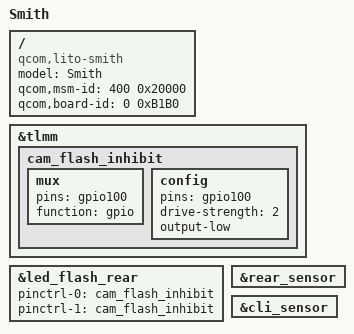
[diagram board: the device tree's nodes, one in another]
/* Copyright (c) 2019, The Linux Foundation. All rights reserved.
 *
 * This program is free software; you can redistribute it and/or modify
 * it under the terms of the GNU General Public License version 2 and
 * only version 2 as published by the Free Software Foundation.
 *
 * This program is distributed in the hope that it will be useful,
 * but WITHOUT ANY WARRANTY; without even the implied warranty of
 * MERCHANTABILITY or FITNESS FOR A PARTICULAR PURPOSE.  See the
 * GNU General Public License for more details.
 */

/dts-v1/;
/plugin/;

#include "lito-smith-common-overlay.dtsi"

/ {
	model = "Smith";
	compatible = "qcom,lito-smith", "qcom,lito-moto", "qcom,lito";
	qcom,msm-id = <400 0x20000>;
	qcom,board-id = <0 0xB1B0>;
};

/*
 * Smith HW rev DVT1B specific changes go here
 */

&tlmm {
	cam_flash_inhibit: cam_flash_inhibit {
		/* INHIBIT */
		mux {
			pins = "gpio100";
			function = "gpio";
		};

		config {
			pins = "gpio100";
			drive-strength = <2>; /* 2 MA */
			output-low;
		};
	};
};

&led_flash_rear {
	pinctrl-names = "cam_default", "cam_suspend";
	pinctrl-0 = <&cam_flash_inhibit>;
	pinctrl-1 = <&cam_flash_inhibit>;
};

/delete-node/ &ois_rear;

&rear_sensor {
	/delete-property/ ois-src;
};

&cli_sensor {
	/delete-property/ ois-src;
};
